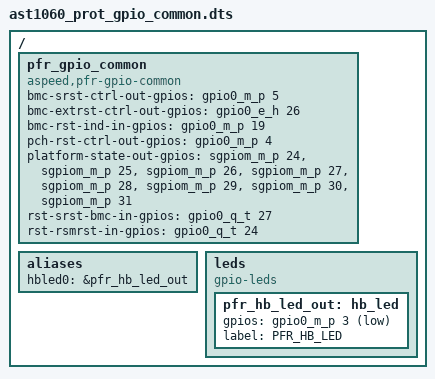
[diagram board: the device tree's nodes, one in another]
/ {
	pfr_gpio_common {
		compatible = "aspeed,pfr-gpio-common";
		bmc-srst-ctrl-out-gpios = <&gpio0_m_p 5 0>; /* GPIO_M5 */
		bmc-extrst-ctrl-out-gpios = <&gpio0_e_h 26 0>; /* GPIO_H2 */
		bmc-rst-ind-in-gpios = <&gpio0_m_p 19 0>; /* GPIO_O3 */
		pch-rst-ctrl-out-gpios = <&gpio0_m_p 4 0>; /* GPIO_M4 */

		platform-state-out-gpios =
			<&sgpiom_m_p 24 0>, <&sgpiom_m_p 25 0>,
			<&sgpiom_m_p 26 0>, <&sgpiom_m_p 27 0>,
			<&sgpiom_m_p 28 0>, <&sgpiom_m_p 29 0>,
			<&sgpiom_m_p 30 0>, <&sgpiom_m_p 31 0>;

		/* NOTICE:
		 * Normally, these two pin should be GPIO_ACTIVE_LOW, but currently this EVB
		 * doesn't produce correct power sequence by itself.
		 */
		rst-srst-bmc-in-gpios = <&gpio0_q_t 27 GPIO_ACTIVE_HIGH>; /* GPIO_T3 */
		rst-rsmrst-in-gpios = <&gpio0_q_t 24 GPIO_ACTIVE_HIGH>; /* GPIO_T0 */
	};

	aliases {
		hbled0 = &pfr_hb_led_out;
	};

	leds {
		compatible = "gpio-leds";

		pfr_hb_led_out: hb_led {
			gpios = <&gpio0_m_p 3 1>; /* GPIO_M3 */
			label = "PFR_HB_LED";
		};
	};
};

